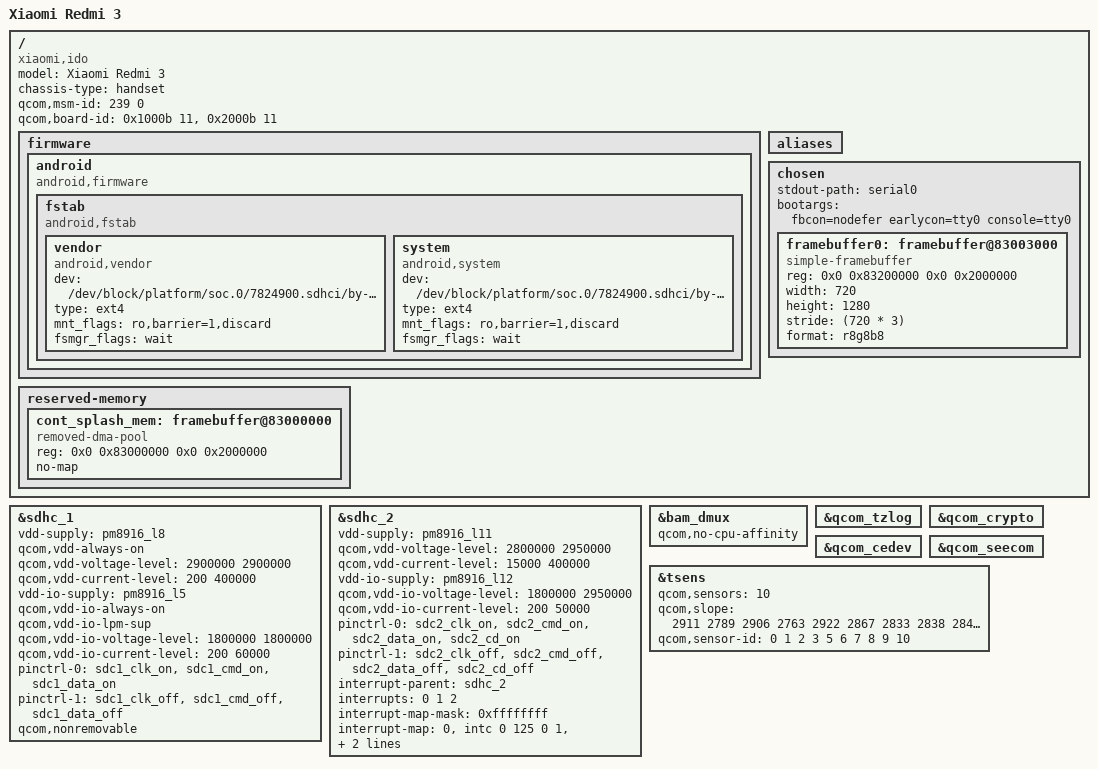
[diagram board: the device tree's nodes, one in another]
// SPDX-License-Identifier: GPL-2.0-only

/dts-v1/;
#include <dt-bindings/clock/msm-clocks-8936.h>
#include <dt-bindings/clock/msm-cpu-clocks-8939.h>
#include "ido/msm8939.dtsi"
#include "ido/msm8939-pinctrl.dtsi"
#include "ido/msm8939-bus.dtsi"
#include "ido/msm8939-cpu.dtsi"
#include "msm8939-ion.dtsi"

/ {
	model = "Xiaomi Redmi 3";
	compatible = "xiaomi,ido", "qcom,msm8939", "qcom,msm8939-qrd-skuk", "qcom,qrd";
	chassis-type = "handset";
	qcom,msm-id = <239 0>;
	qcom,board-id = <0x1000b 11>, <0x2000b 11>;

       firmware: firmware {
                 android {
                         compatible = "android,firmware";
                         fstab {
                                 compatible = "android,fstab";
                                 vendor {
                                         compatible = "android,vendor";
                                         dev = "/dev/block/platform/soc.0/7824900.sdhci/by-name/vendor";
                                         type = "ext4";
                                         mnt_flags = "ro,barrier=1,discard";
                                         fsmgr_flags = "wait";
                                         status = "ok";
                                 };
                                 system {
                                         compatible = "android,system";
                                         dev = "/dev/block/platform/soc.0/7824900.sdhci/by-name/system";
                                        type = "ext4";
                                     mnt_flags = "ro,barrier=1,discard";
                                       fsmgr_flags = "wait";
                                      status = "ok";
                                 };
                        };
                };
       };

	aliases {
	};

	chosen {
		stdout-path = "serial0";
		bootargs = "fbcon=nodefer earlycon=tty0 console=tty0";
		#address-cells = <2>;
		#size-cells = <2>;
		ranges;

		framebuffer0: framebuffer@83003000 {
			status= "okay";
			compatible = "simple-framebuffer";
			reg = <0x0 0x83200000 0x0 0x2000000>;
			width = <720>;
			height = <1280>;
			stride = <(720 * 3)>;
			format = "r8g8b8";
		};

	};

    reserved-memory {
		cont_splash_mem: framebuffer@83000000 {
			compatible = "removed-dma-pool";
			reg = <0x0 0x83000000 0x0 0x2000000>;
			no-map;
		};
	};

};

&sdhc_1 {
	vdd-supply = <&pm8916_l8>;
	qcom,vdd-always-on;
	qcom,vdd-voltage-level = <2900000 2900000>;
	qcom,vdd-current-level = <200 400000>;

	vdd-io-supply = <&pm8916_l5>;
	qcom,vdd-io-always-on;
	qcom,vdd-io-lpm-sup;
	qcom,vdd-io-voltage-level = <1800000 1800000>;
	qcom,vdd-io-current-level = <200 60000>;

	pinctrl-names = "active", "sleep";
	pinctrl-0 = <&sdc1_clk_on &sdc1_cmd_on &sdc1_data_on>;
	pinctrl-1 = <&sdc1_clk_off &sdc1_cmd_off &sdc1_data_off>;

	qcom,nonremovable;

	status = "ok";
};

&sdhc_2 {
	vdd-supply = <&pm8916_l11>;
	qcom,vdd-voltage-level = <2800000 2950000>;
	qcom,vdd-current-level = <15000 400000>;

	vdd-io-supply = <&pm8916_l12>;
	qcom,vdd-io-voltage-level = <1800000 2950000>;
	qcom,vdd-io-current-level = <200 50000>;

	pinctrl-names = "active", "sleep";
	pinctrl-0 = <&sdc2_clk_on &sdc2_cmd_on &sdc2_data_on &sdc2_cd_on>;
	pinctrl-1 = <&sdc2_clk_off &sdc2_cmd_off &sdc2_data_off &sdc2_cd_off>;

	#address-cells = <0>;
	interrupt-parent = <&sdhc_2>;
	interrupts = <0 1 2>;
	#interrupt-cells = <1>;
	interrupt-map-mask = <0xffffffff>;
	interrupt-map = <0 &intc 0 125 0
			1 &intc 0 221 0
			2 &msm_gpio 38 0>;
	interrupt-names = "hc_irq", "pwr_irq", "status_irq";
	cd-gpios = <&msm_gpio 38 0x1>;

	status = "ok";
};

&bam_dmux {
	qcom,no-cpu-affinity;
};

&qcom_tzlog {
	status = "okay";
};

&qcom_crypto {
	status = "okay";
};

&qcom_cedev {
	status = "okay";
};

&qcom_seecom {
	status = "okay";
};

&tsens {
	qcom,sensors = <10>;
	qcom,slope = <2911 2789 2906 2763 2922 2867 2833 2838 2840 2852>;
	qcom,sensor-id = <0 1 2 3 5 6 7 8 9 10>;
};

&firmware {
	android {
		fstab {
			vendor {
				dev = "/dev/block/platform/soc.0/7824900.sdhci/by-name/cust";
			};
		};
	};
};

